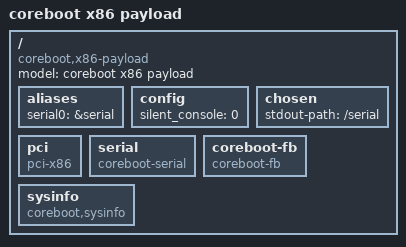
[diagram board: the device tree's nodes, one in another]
// SPDX-License-Identifier: GPL-2.0+
/*
 * Copyright (C) 2018, Bin Meng <bmeng.cn@gmail.com>
 *
 * Generic coreboot payload device tree for x86 targets
 */

/dts-v1/;

/include/ "skeleton.dtsi"
/include/ "keyboard.dtsi"
/include/ "pcspkr.dtsi"
/include/ "reset.dtsi"
/include/ "rtc.dtsi"

#include "tsc_timer.dtsi"

/ {
	model = "coreboot x86 payload";
	compatible = "coreboot,x86-payload";

	aliases {
		serial0 = &serial;
	};

	config {
		silent_console = <0>;
	};

	chosen {
		stdout-path = "/serial";
	};

	pci {
		compatible = "pci-x86";
		bootph-all;
	};

	serial: serial {
		bootph-all;
		compatible = "coreboot-serial";
	};

	coreboot-fb {
		bootph-some-ram;
		compatible = "coreboot-fb";
	};

	sysinfo {
		compatible = "coreboot,sysinfo";
	};
};
